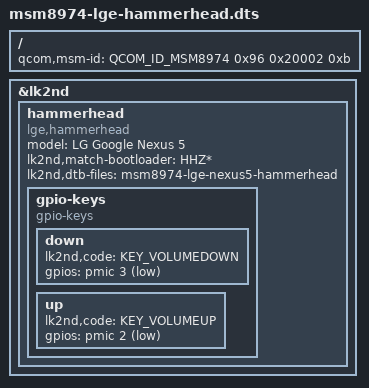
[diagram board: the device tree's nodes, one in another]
// SPDX-License-Identifier: BSD-3-Clause

#include <skeleton64.dtsi>
#include <lk2nd.dtsi>

/*
 * To build for hammerhead, add LK2ND_QCDTBS="" to your make cmdline
 * hammerhead does not work with qcdtbs enabled.
 */

/ {
	qcom,msm-id = <QCOM_ID_MSM8974 0x96 0x20002 0xb>;
};

&lk2nd {
	hammerhead {
		model = "LG Google Nexus 5";
		compatible = "lge,hammerhead";
		lk2nd,match-bootloader = "HHZ*";

		lk2nd,dtb-files = "msm8974-lge-nexus5-hammerhead";

		gpio-keys {
			compatible = "gpio-keys";
			down {
				lk2nd,code = <KEY_VOLUMEDOWN>;
				gpios = <&pmic 3 (GPIO_ACTIVE_LOW | GPIO_PULL_UP)>;
			};

			up {
				lk2nd,code = <KEY_VOLUMEUP>;
				gpios = <&pmic 2 (GPIO_ACTIVE_LOW | GPIO_PULL_UP)>;
			};
		};
	};
};
